# DMASS_DTHE_DMASS_DTHE_DTHE_DTHE_CFG_SM3_WRAP_VBUSP_EIP_52_SM3_40809000h register map
Vendor: Texas Instruments
Peripheral module from a debugger description file (folder am62L).
Registers are 32-bit, write-only, reset 0x0 unless marked. A register's access mark holds for its fields unless they carry their own. Offsets are as the file gives them; lines under a group give offsets from that group; [hi:lo] are bit positions; {n}, {i} and the like mark numbered series; 'fields as' and 'values as' point back to an identical list; <NAME> marks a mode.

## DMASS_DTHE_DTHE_DTHE_CFG_SM3_WRAP_VBUSP_EIP_52_SM3
{0x0+4i} DMASS_DTHE_DTHE_DTHE_CFG_SM3_WRAP_VBUSP_EIP_52_SM3_SM3_DATA_IN_{i} (i=0..15) — Data in register {i}
  [31:0] DATA_IN — Data In [{32i+31}:{32i}]
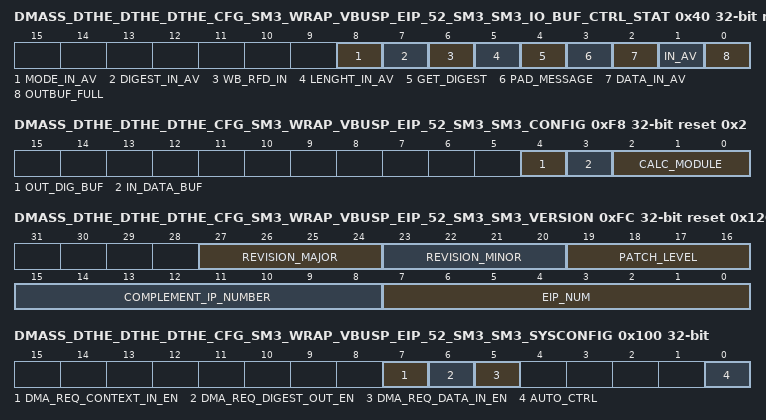
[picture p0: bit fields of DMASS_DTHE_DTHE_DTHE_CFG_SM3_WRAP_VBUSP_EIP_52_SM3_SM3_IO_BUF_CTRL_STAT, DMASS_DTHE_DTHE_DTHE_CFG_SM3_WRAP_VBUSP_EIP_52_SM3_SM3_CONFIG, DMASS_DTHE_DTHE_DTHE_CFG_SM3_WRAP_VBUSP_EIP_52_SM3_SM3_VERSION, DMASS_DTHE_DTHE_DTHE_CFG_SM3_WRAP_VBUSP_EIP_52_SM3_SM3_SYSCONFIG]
0x40 DMASS_DTHE_DTHE_DTHE_CFG_SM3_WRAP_VBUSP_EIP_52_SM3_SM3_IO_BUF_CTRL_STAT access not given reset 0x40 — Control Status Register
  [8] MODE_IN_AV — mode_in_av (access R/W1TS)
  [7] DIGEST_IN_AV — Digest in available (access R/W1TS)
  [6] WB_RFD_IN ro — Ready for data in
  [5] LENGHT_IN_AV — Length in available (access R/W1TS)
  [4] GET_DIGEST — Get Digest (access R/W1TS)
  [3] PAD_MESSAGE — Pad Message (access R/W1TS)
  [2] DATA_IN_AV — Data Input Available (access R/W1TS)
  [1] IN_AV — Control Input Available (access R/W1TS)
  [0] OUTBUF_FULL — Output Buffer Full (access R/W1TC)
0x44 DMASS_DTHE_DTHE_DTHE_CFG_SM3_WRAP_VBUSP_EIP_52_SM3_SM3_MODE_IN — Mode register
  [0] NEW_HASH
0x48 DMASS_DTHE_DTHE_DTHE_CFG_SM3_WRAP_VBUSP_EIP_52_SM3_SM3_LENGTH_IN_0 — Length register 0
  [31:0] LENTH_IN_0 — Lower 32 bits of the message length in unit of bits
0x4C DMASS_DTHE_DTHE_DTHE_CFG_SM3_WRAP_VBUSP_EIP_52_SM3_SM3_LENGTH_IN_1 — Length register 1
  [31:0] LENTH_IN_1 — Upper 32 bits of the message length in unit of bits
{0x50+4i} DMASS_DTHE_DTHE_DTHE_CFG_SM3_WRAP_VBUSP_EIP_52_SM3_SM3_DIGEST_IN_{i} (i=0..7) — Digest in register {i}
  [31:0] DIGEST_IN — Digest in [{32i+31}:{32i}]
{0x70+4i} DMASS_DTHE_DTHE_DTHE_CFG_SM3_WRAP_VBUSP_EIP_52_SM3_SM3_DIGEST_OUT_{i} ro (i=0..7) — Digest out register {i}
  [31:0] DIGEST_OUT — Digest out [{32i+31}:{32i}]
0xF8 DMASS_DTHE_DTHE_DTHE_CFG_SM3_WRAP_VBUSP_EIP_52_SM3_SM3_CONFIG ro reset 0x2 — Hardware Configuration Register
  [4] OUT_DIG_BUF — Output digest buffer present
  [3] IN_DATA_BUF — Input buffer shared with round buffer
  [2:0] CALC_MODULE — Number of incorporated calculation modules
0xFC DMASS_DTHE_DTHE_DTHE_CFG_SM3_WRAP_VBUSP_EIP_52_SM3_SM3_VERSION ro reset 0x120CB34 — Hardware Version Number
  [27:24] REVISION_MAJOR — Hardware Major Revision
  [23:20] REVISION_MINOR — Hardware Minor Revision
  [19:16] PATCH_LEVEL — Hardware Patch Revision
  [15:8] COMPLEMENT_IP_NUMBER — Complement of EIP Number
  [7:0] EIP_NUM — EIP Number
0x100 DMASS_DTHE_DTHE_DTHE_CFG_SM3_WRAP_VBUSP_EIP_52_SM3_SM3_SYSCONFIG rw — Enable register for the different dma request lines and the automatic trigger of the core.
  [7] DMA_REQ_CONTEXT_IN_EN — Enable DMA Request for context input.
  [6] DMA_REQ_DIGEST_OUT_EN — Enable DMA request for hash or digest output.
  [5] DMA_REQ_DATA_IN_EN — Enable DMA request for data input.
  [0] AUTO_CTRL — Turn on mode where HW can automatically issue dma request and/or interrupt. When set to 1, dma requests or sm3_intr will assert to request new push or pop of data. If set to 0, SW will need to commit the inputs manually through Writing/Reading/polling the bits in the SM3_IO_BUF_CTRL_STAT register. There is no dma request or interrupt when the auto_ctrl is 0.
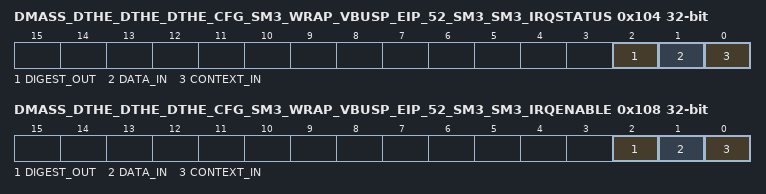
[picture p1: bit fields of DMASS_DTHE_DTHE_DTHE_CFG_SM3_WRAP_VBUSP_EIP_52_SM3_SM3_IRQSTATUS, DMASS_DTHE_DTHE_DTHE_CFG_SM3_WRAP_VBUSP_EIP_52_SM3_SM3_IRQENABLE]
0x104 DMASS_DTHE_DTHE_DTHE_CFG_SM3_WRAP_VBUSP_EIP_52_SM3_SM3_IRQSTATUS rw — contains the raw status of each interrupt source
  [2] DIGEST_OUT — When set to 1, indicates the digest result is available from the output registers.
  [1] DATA_IN — When set to 1, indicates the data buffer is ready to receive the next 64 byte data block.
  [0] CONTEXT_IN — When set to 1, indicates that the context input register is available for new context for the next packet.
0x108 DMASS_DTHE_DTHE_DTHE_CFG_SM3_WRAP_VBUSP_EIP_52_SM3_SM3_IRQENABLE rw — contains an enable bit for each unique source for the sm3_intr output. This enable is independent of the dma request. The auto_ctrl in SYSCONFIG must be set to 1 for interrupt to be generated.
  [2] DIGEST_OUT — Data Out Interrupt Enable. Set to 1 if sm3_intr should be asserted when there is digest out request.
  [1] DATA_IN — Data In Interrupt Enable. Set to 1 if sm3_intr should be asserted when there is new data in request.
  [0] CONTEXT_IN — Context In Interrupt Enable. Set to 1 if sm3_intr should be asserted when there is new context in request.
